VERSION ""

NS_ :

BS_:

BU_:
VAL_TABLE_ CurDivValid 1 "Valid" 0 "Invalid" ;
VAL_TABLE_ CurDivValid 1 "Description for the value '0x1'" 0 "Invalid" ;
VAL_TABLE_ Validity 1 "Valid" 0 "Invalid" ;
VAL_TABLE_ Model_Degree 2 "3rd-Degree Model" 1 "Linear model" 0 "Parabolic Model" ;
VAL_TABLE_ Quality 3 "High Quality" 2 "High Quality" 1 "Low Quality" 0 "Low Quality" ;
VAL_TABLE_ Lane_Type 6 "Invalid" 5 "Botts' dots" 4 "Double lane mark" 3 "Road edge" 2 "Undecided" 1 "Solid" 0 "Dashed" ;
VAL_TABLE_ Ref_Point_2_Validity 1 "Valid" 0 "Invalid" ;
VAL_TABLE_ Ref_Point_1_Validity 1 "Valid" 0 "Invalid" ;
VAL_TABLE_ View_Ragne_Availability 1 "Valid" 0 "Not Valid" ;
VAL_TABLE_ Model_Degree 2 "3rd-degree model" 1 "Linear model" 0 "Parabolic model" ;
VAL_TABLE_ Quality 3 "High quality" 2 "High quality" 1 "Low quality" 0 "Low quality" ;
VAL_TABLE_ Lane_Type 6 "invalid" 5 "Bott's Dots" 4 "Double Lane" 3 "Road Edge" 2 "undecided" 1 "Solid" 0 "Dashed" ;

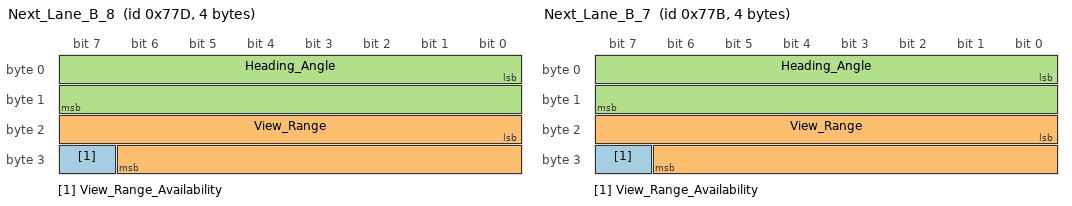
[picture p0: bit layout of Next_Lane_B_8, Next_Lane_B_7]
BO_ 1917 Next_Lane_B_8: 4 Vector__XXX
 SG_ View_Range_Availability : 31|1@1+ (1,0) [0|0] "" Vector__XXX
 SG_ View_Range : 16|15@1+ (0.00390625,0) [0|127.99609375] "meter" Vector__XXX
 SG_ Heading_Angle : 0|16@1+ (0.0009765625,-31.9990234375) [-0.357|0.357] "radians" Vector__XXX

BO_ 1915 Next_Lane_B_7: 4 Vector__XXX
 SG_ View_Range_Availability : 31|1@1+ (1,0) [0|0] "" Vector__XXX
 SG_ View_Range : 16|15@1+ (0.00390625,0) [0|127.99609375] "meter" Vector__XXX
 SG_ Heading_Angle : 0|16@1+ (0.0009765625,-31.9990234375) [-0.357|0.357] "radians" Vector__XXX

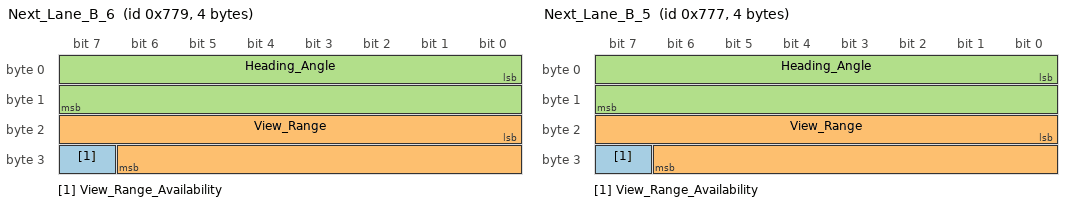
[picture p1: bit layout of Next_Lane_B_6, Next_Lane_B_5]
BO_ 1913 Next_Lane_B_6: 4 Vector__XXX
 SG_ View_Range_Availability : 31|1@1+ (1,0) [0|0] "" Vector__XXX
 SG_ View_Range : 16|15@1+ (0.00390625,0) [0|127.99609375] "meter" Vector__XXX
 SG_ Heading_Angle : 0|16@1+ (0.0009765625,-31.9990234375) [-0.357|0.357] "radians" Vector__XXX

BO_ 1911 Next_Lane_B_5: 4 Vector__XXX
 SG_ View_Range_Availability : 31|1@1+ (1,0) [0|0] "" Vector__XXX
 SG_ View_Range : 16|15@1+ (0.00390625,0) [0|127.99609375] "meter" Vector__XXX
 SG_ Heading_Angle : 0|16@1+ (0.0009765625,-31.9990234375) [-0.357|0.357] "radians" Vector__XXX

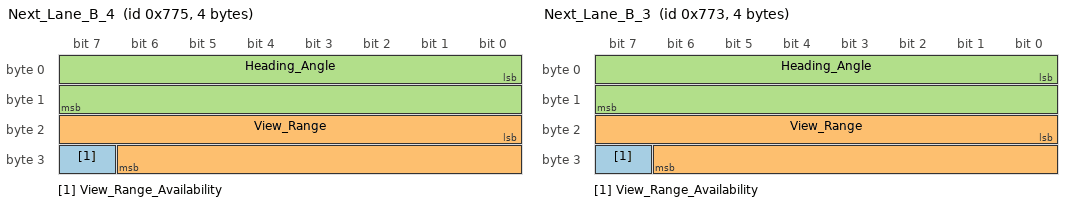
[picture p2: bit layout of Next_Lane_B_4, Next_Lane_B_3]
BO_ 1909 Next_Lane_B_4: 4 Vector__XXX
 SG_ View_Range_Availability : 31|1@1+ (1,0) [0|0] "" Vector__XXX
 SG_ View_Range : 16|15@1+ (0.00390625,0) [0|127.99609375] "meter" Vector__XXX
 SG_ Heading_Angle : 0|16@1+ (0.0009765625,-31.9990234375) [-0.357|0.357] "radians" Vector__XXX

BO_ 1907 Next_Lane_B_3: 4 Vector__XXX
 SG_ View_Range_Availability : 31|1@1+ (1,0) [0|0] "" Vector__XXX
 SG_ View_Range : 16|15@1+ (0.00390625,0) [0|127.99609375] "meter" Vector__XXX
 SG_ Heading_Angle : 0|16@1+ (0.0009765625,-31.9990234375) [-0.357|0.357] "radians" Vector__XXX

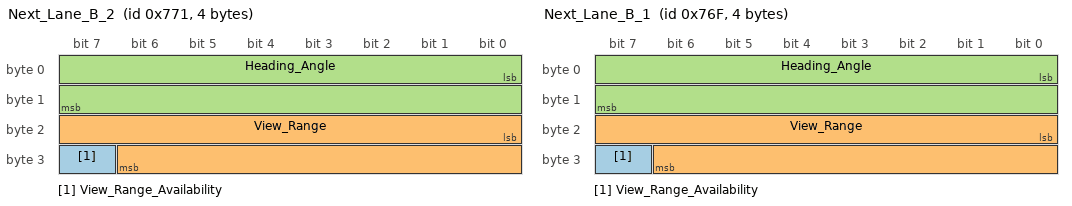
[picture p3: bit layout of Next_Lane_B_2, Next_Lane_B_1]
BO_ 1905 Next_Lane_B_2: 4 Vector__XXX
 SG_ View_Range_Availability : 31|1@1+ (1,0) [0|0] "" Vector__XXX
 SG_ View_Range : 16|15@1+ (0.00390625,0) [0|127.99609375] "meter" Vector__XXX
 SG_ Heading_Angle : 0|16@1+ (0.0009765625,-31.9990234375) [-0.357|0.357] "radians" Vector__XXX

BO_ 1903 Next_Lane_B_1: 4 Vector__XXX
 SG_ View_Range_Availability : 31|1@1+ (1,0) [0|0] "" Vector__XXX
 SG_ View_Range : 16|15@1+ (0.00390625,0) [0|127.99609375] "meter" Vector__XXX
 SG_ Heading_Angle : 0|16@1+ (0.0009765625,-31.9990234375) [-0.357|0.357] "radians" Vector__XXX

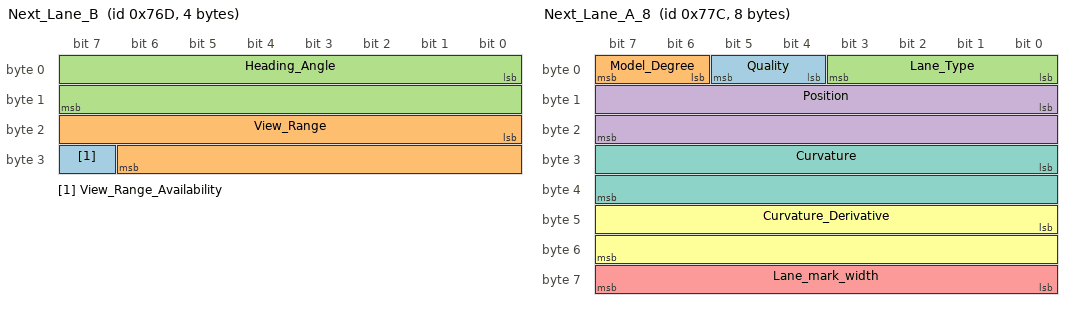
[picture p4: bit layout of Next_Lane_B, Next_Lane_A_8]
BO_ 1901 Next_Lane_B: 4 Vector__XXX
 SG_ View_Range_Availability : 31|1@1+ (1,0) [0|0] "" Vector__XXX
 SG_ View_Range : 16|15@1+ (0.00390625,0) [0|127.99609375] "meter" Vector__XXX
 SG_ Heading_Angle : 0|16@1+ (0.0009765625,-31.9990234375) [-0.357|0.357] "radians" Vector__XXX

BO_ 1916 Next_Lane_A_8: 8 Vector__XXX
 SG_ Quality : 4|2@1+ (1,0) [0|0] "" Vector__XXX
 SG_ Model_Degree : 6|2@1+ (1,0) [0|0] "" Vector__XXX
 SG_ Lane_Type : 0|4@1+ (1,0) [0|0] "" Vector__XXX
 SG_ Position : 8|16@1- (0.00390625,0) [-128|127] "meter" Vector__XXX
 SG_ Lane_mark_width : 56|8@1+ (0.01,0) [0|2.5] "meter" Vector__XXX
 SG_ Curvature_Derivative : 40|16@1+ (3.7252902985E-009,-0.00012206658721) [-0.00012|0.00012] "1/meter^2" Vector__XXX
 SG_ Curvature : 24|16@1+ (9.765625E-007,-0.031999023438) [-0.02|0.02] "1/meter" Vector__XXX

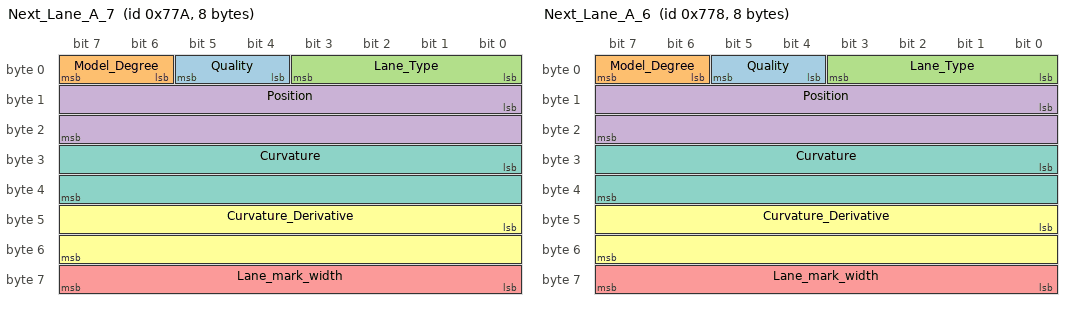
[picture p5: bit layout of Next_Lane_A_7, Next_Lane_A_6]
BO_ 1914 Next_Lane_A_7: 8 Vector__XXX
 SG_ Quality : 4|2@1+ (1,0) [0|0] "" Vector__XXX
 SG_ Model_Degree : 6|2@1+ (1,0) [0|0] "" Vector__XXX
 SG_ Lane_Type : 0|4@1+ (1,0) [0|0] "" Vector__XXX
 SG_ Position : 8|16@1- (0.00390625,0) [-128|127] "meter" Vector__XXX
 SG_ Lane_mark_width : 56|8@1+ (0.01,0) [0|2.5] "meter" Vector__XXX
 SG_ Curvature_Derivative : 40|16@1+ (3.7252902985E-009,-0.00012206658721) [-0.00012|0.00012] "1/meter^2" Vector__XXX
 SG_ Curvature : 24|16@1+ (9.765625E-007,-0.031999023438) [-0.02|0.02] "1/meter" Vector__XXX

BO_ 1912 Next_Lane_A_6: 8 Vector__XXX
 SG_ Quality : 4|2@1+ (1,0) [0|0] "" Vector__XXX
 SG_ Model_Degree : 6|2@1+ (1,0) [0|0] "" Vector__XXX
 SG_ Lane_Type : 0|4@1+ (1,0) [0|0] "" Vector__XXX
 SG_ Position : 8|16@1- (0.00390625,0) [-128|127] "meter" Vector__XXX
 SG_ Lane_mark_width : 56|8@1+ (0.01,0) [0|2.5] "meter" Vector__XXX
 SG_ Curvature_Derivative : 40|16@1+ (3.7252902985E-009,-0.00012206658721) [-0.00012|0.00012] "1/meter^2" Vector__XXX
 SG_ Curvature : 24|16@1+ (9.765625E-007,-0.031999023438) [-0.02|0.02] "1/meter" Vector__XXX

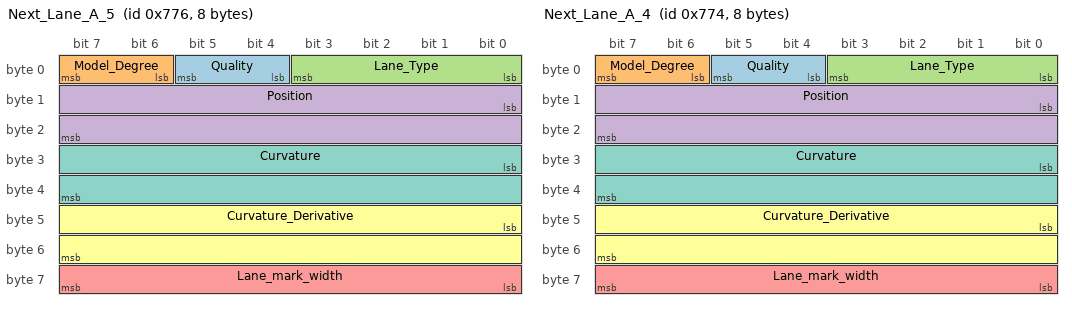
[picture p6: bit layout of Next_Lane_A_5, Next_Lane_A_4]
BO_ 1910 Next_Lane_A_5: 8 Vector__XXX
 SG_ Quality : 4|2@1+ (1,0) [0|0] "" Vector__XXX
 SG_ Model_Degree : 6|2@1+ (1,0) [0|0] "" Vector__XXX
 SG_ Lane_Type : 0|4@1+ (1,0) [0|0] "" Vector__XXX
 SG_ Position : 8|16@1- (0.00390625,0) [-128|127] "meter" Vector__XXX
 SG_ Lane_mark_width : 56|8@1+ (0.01,0) [0|2.5] "meter" Vector__XXX
 SG_ Curvature_Derivative : 40|16@1+ (3.7252902985E-009,-0.00012206658721) [-0.00012|0.00012] "1/meter^2" Vector__XXX
 SG_ Curvature : 24|16@1+ (9.765625E-007,-0.031999023438) [-0.02|0.02] "1/meter" Vector__XXX

BO_ 1908 Next_Lane_A_4: 8 Vector__XXX
 SG_ Quality : 4|2@1+ (1,0) [0|0] "" Vector__XXX
 SG_ Model_Degree : 6|2@1+ (1,0) [0|0] "" Vector__XXX
 SG_ Lane_Type : 0|4@1+ (1,0) [0|0] "" Vector__XXX
 SG_ Position : 8|16@1- (0.00390625,0) [-128|127] "meter" Vector__XXX
 SG_ Lane_mark_width : 56|8@1+ (0.01,0) [0|2.5] "meter" Vector__XXX
 SG_ Curvature_Derivative : 40|16@1+ (3.7252902985E-009,-0.00012206658721) [-0.00012|0.00012] "1/meter^2" Vector__XXX
 SG_ Curvature : 24|16@1+ (9.765625E-007,-0.031999023438) [-0.02|0.02] "1/meter" Vector__XXX

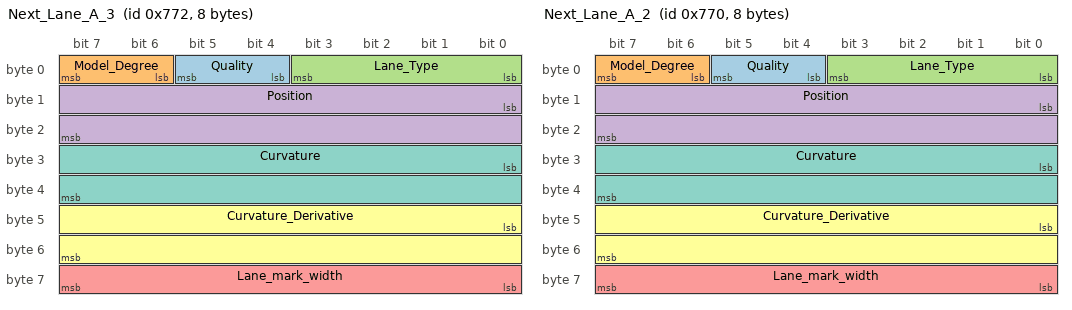
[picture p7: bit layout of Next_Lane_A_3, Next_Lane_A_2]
BO_ 1906 Next_Lane_A_3: 8 Vector__XXX
 SG_ Quality : 4|2@1+ (1,0) [0|0] "" Vector__XXX
 SG_ Model_Degree : 6|2@1+ (1,0) [0|0] "" Vector__XXX
 SG_ Lane_Type : 0|4@1+ (1,0) [0|0] "" Vector__XXX
 SG_ Position : 8|16@1- (0.00390625,0) [-128|127] "meter" Vector__XXX
 SG_ Lane_mark_width : 56|8@1+ (0.01,0) [0|2.5] "meter" Vector__XXX
 SG_ Curvature_Derivative : 40|16@1+ (3.7252902985E-009,-0.00012206658721) [-0.00012|0.00012] "1/meter^2" Vector__XXX
 SG_ Curvature : 24|16@1+ (9.765625E-007,-0.031999023438) [-0.02|0.02] "1/meter" Vector__XXX

BO_ 1904 Next_Lane_A_2: 8 Vector__XXX
 SG_ Quality : 4|2@1+ (1,0) [0|0] "" Vector__XXX
 SG_ Model_Degree : 6|2@1+ (1,0) [0|0] "" Vector__XXX
 SG_ Lane_Type : 0|4@1+ (1,0) [0|0] "" Vector__XXX
 SG_ Position : 8|16@1- (0.00390625,0) [-128|127] "meter" Vector__XXX
 SG_ Lane_mark_width : 56|8@1+ (0.01,0) [0|2.5] "meter" Vector__XXX
 SG_ Curvature_Derivative : 40|16@1+ (3.7252902985E-009,-0.00012206658721) [-0.00012|0.00012] "1/meter^2" Vector__XXX
 SG_ Curvature : 24|16@1+ (9.765625E-007,-0.031999023438) [-0.02|0.02] "1/meter" Vector__XXX

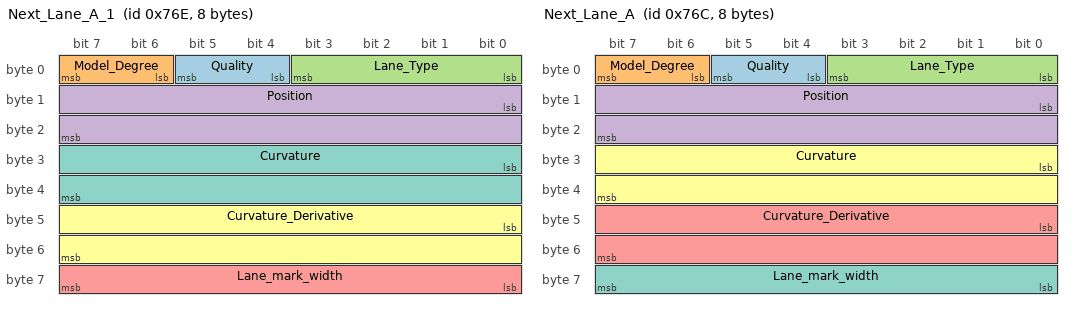
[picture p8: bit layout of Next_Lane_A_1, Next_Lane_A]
BO_ 1902 Next_Lane_A_1: 8 Vector__XXX
 SG_ Quality : 4|2@1+ (1,0) [0|0] "" Vector__XXX
 SG_ Model_Degree : 6|2@1+ (1,0) [0|0] "" Vector__XXX
 SG_ Lane_Type : 0|4@1+ (1,0) [0|0] "" Vector__XXX
 SG_ Position : 8|16@1- (0.00390625,0) [-128|127] "meter" Vector__XXX
 SG_ Lane_mark_width : 56|8@1+ (0.01,0) [0|2.5] "meter" Vector__XXX
 SG_ Curvature_Derivative : 40|16@1+ (3.7252902985E-009,-0.00012206658721) [-0.00012|0.00012] "1/meter^2" Vector__XXX
 SG_ Curvature : 24|16@1+ (9.765625E-007,-0.031999023438) [-0.02|0.02] "1/meter" Vector__XXX

BO_ 1900 Next_Lane_A: 8 Vector__XXX
 SG_ Quality : 4|2@1+ (1,0) [0|0] "" Vector__XXX
 SG_ Model_Degree : 6|2@1+ (1,0) [0|0] "" Vector__XXX
 SG_ Lane_Type : 0|4@1+ (1,0) [0|0] "" Vector__XXX
 SG_ Position : 8|16@1- (0.00390625,0) [-128|127] "meter" Vector__XXX
 SG_ Curvature_Derivative : 40|16@1+ (3.7252902985E-009,-0.00012206658721) [-0.00012|0.00012] "1/meter^2" Vector__XXX
 SG_ Curvature : 24|16@1+ (9.765625E-007,-0.031999023438) [-0.02|0.02] "1/meter" Vector__XXX
 SG_ Lane_mark_width : 56|8@1+ (0.01,0) [0|2.5] "meter" Vector__XXX

BO_ 1899 Num_Of_Next_Lane_Marks_Reported: 1 Vector__XXX
 SG_ Num_Of_Next_Lane_Mark_Reported : 7|8@0+ (1,0) [0|0] "Number of next lane markers" Vector__XXX

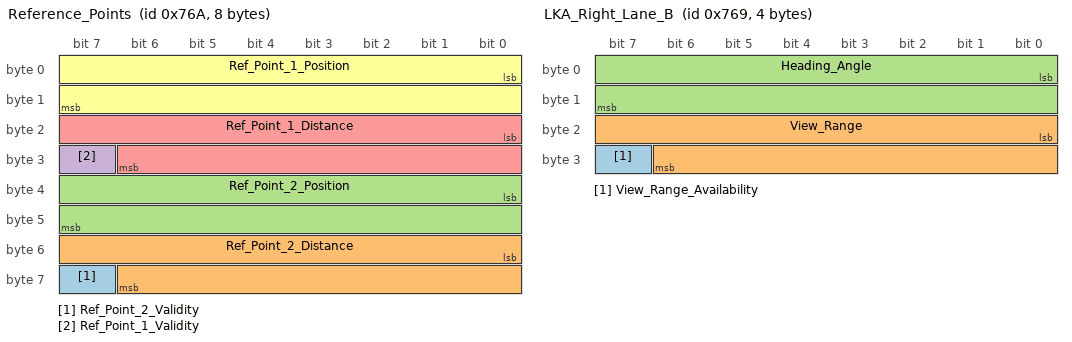
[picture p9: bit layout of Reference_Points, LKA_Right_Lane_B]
BO_ 1898 Reference_Points: 8 Vector__XXX
 SG_ Ref_Point_2_Validity : 63|1@0+ (1,0) [0|0] "" Vector__XXX
 SG_ Ref_Point_2_Distance : 48|15@1+ (0.00390625,0) [0|127.99609375] "meters" Vector__XXX
 SG_ Ref_Point_2_Position : 32|16@1+ (0.00390625,-127.99609375) [-127.99609375|128] "meters" Vector__XXX
 SG_ Ref_Point_1_Validity : 31|1@0+ (1,0) [0|0] "" Vector__XXX
 SG_ Ref_Point_1_Distance : 16|15@1+ (0.00390625,0) [0|127.99609375] "meters" Vector__XXX
 SG_ Ref_Point_1_Position : 0|16@1+ (0.00390625,-127.99609375) [-127.99609375|128] "meters" Vector__XXX

BO_ 1897 LKA_Right_Lane_B: 4 Vector__XXX
 SG_ View_Range_Availability : 31|1@1+ (1,0) [0|0] "" Vector__XXX
 SG_ View_Range : 16|15@1+ (0.00390625,0) [0|127.99609375] "meter" Vector__XXX
 SG_ Heading_Angle : 0|16@1+ (0.0009765625,-31.9990234375) [-0.357|0.357] "radians" Vector__XXX

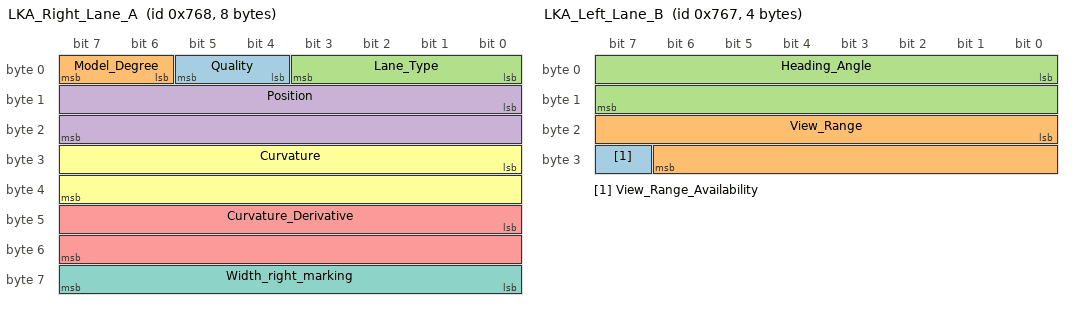
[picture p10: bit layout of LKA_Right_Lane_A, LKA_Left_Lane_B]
BO_ 1896 LKA_Right_Lane_A: 8 Vector__XXX
 SG_ Quality : 4|2@1+ (1,0) [0|0] "" Vector__XXX
 SG_ Model_Degree : 6|2@1+ (1,0) [0|0] "" Vector__XXX
 SG_ Lane_Type : 0|4@1+ (1,0) [0|0] "" Vector__XXX
 SG_ Position : 8|16@1- (0.00390625,0) [-128|127] "meter" Vector__XXX
 SG_ Curvature_Derivative : 40|16@1+ (3.7252902985E-009,-0.00012206658721) [-0.00012|0.00012] "1/meter^2" Vector__XXX
 SG_ Curvature : 24|16@1+ (9.765625E-007,-0.031999023438) [-0.02|0.02] "1/meter" Vector__XXX
 SG_ Width_right_marking : 56|8@1+ (0.01,0) [0|2.55] "m" Vector__XXX

BO_ 1895 LKA_Left_Lane_B: 4 Vector__XXX
 SG_ View_Range_Availability : 31|1@1+ (1,0) [0|0] "" Vector__XXX
 SG_ View_Range : 16|15@1+ (0.00390625,0) [0|127.99609375] "meter" Vector__XXX
 SG_ Heading_Angle : 0|16@1+ (0.0009765625,-31.9990234375) [-0.357|0.357] "radians" Vector__XXX

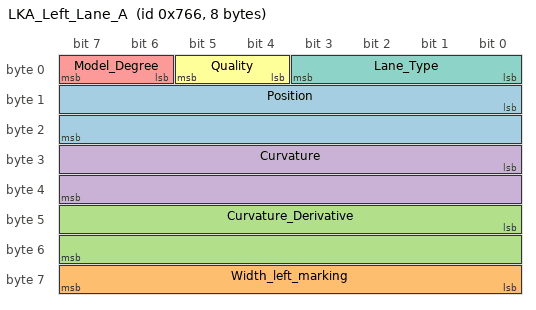
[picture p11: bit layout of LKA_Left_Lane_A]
BO_ 1894 LKA_Left_Lane_A: 8 Vector__XXX
 SG_ Position : 8|16@1- (0.00390625,0) [-128|127] "meter" Vector__XXX
 SG_ Width_left_marking : 56|8@1+ (0.01,0) [0|2.5] "m" Vector__XXX
 SG_ Curvature_Derivative : 40|16@1+ (3.7252902985E-009,-0.00012206658721) [-0.00012|0.00012] "1/meter^2" Vector__XXX
 SG_ Curvature : 24|16@1+ (9.765625E-007,-0.031999023438) [-0.02|0.02] "1/meter" Vector__XXX
 SG_ Model_Degree : 6|2@1+ (1,0) [0|0] "" Vector__XXX
 SG_ Quality : 4|2@1+ (1,0) [0|0] "" Vector__XXX
 SG_ Lane_Type : 0|4@1+ (1,0) [0|0] "" Vector__XXX

BA_DEF_  "BusType" STRING ;
BA_DEF_DEF_  "BusType" "CAN";
VAL_ 1917 View_Range_Availability 1 "Valid" 0 "Not Valid" ;
VAL_ 1915 View_Range_Availability 1 "Valid" 0 "Not Valid" ;
VAL_ 1913 View_Range_Availability 1 "Valid" 0 "Not Valid" ;
VAL_ 1911 View_Range_Availability 1 "Valid" 0 "Not Valid" ;
VAL_ 1909 View_Range_Availability 1 "Valid" 0 "Not Valid" ;
VAL_ 1907 View_Range_Availability 1 "Valid" 0 "Not Valid" ;
VAL_ 1905 View_Range_Availability 1 "Valid" 0 "Not Valid" ;
VAL_ 1903 View_Range_Availability 1 "Valid" 0 "Not Valid" ;
VAL_ 1901 View_Range_Availability 1 "Valid" 0 "Not Valid" ;
VAL_ 1916 Quality 3 "High quality" 2 "High quality" 1 "Low quality" 0 "Low quality" ;
VAL_ 1916 Model_Degree 2 "3rd-degree model" 1 "Linear model" 0 "Parabolic model" ;
VAL_ 1916 Lane_Type 6 "invalid" 5 "Bott's Dots" 4 "Double Lane" 3 "Road Edge" 2 "undecided" 1 "Solid" 0 "Dashed" ;
VAL_ 1914 Quality 3 "High quality" 2 "High quality" 1 "Low quality" 0 "Low quality" ;
VAL_ 1914 Model_Degree 2 "3rd-degree model" 1 "Linear model" 0 "Parabolic model" ;
VAL_ 1914 Lane_Type 6 "invalid" 5 "Bott's Dots" 4 "Double Lane" 3 "Road Edge" 2 "undecided" 1 "Solid" 0 "Dashed" ;
VAL_ 1912 Quality 3 "High quality" 2 "High quality" 1 "Low quality" 0 "Low quality" ;
VAL_ 1912 Model_Degree 2 "3rd-degree model" 1 "Linear model" 0 "Parabolic model" ;
VAL_ 1912 Lane_Type 6 "invalid" 5 "Bott's Dots" 4 "Double Lane" 3 "Road Edge" 2 "undecided" 1 "Solid" 0 "Dashed" ;
VAL_ 1910 Quality 3 "High quality" 2 "High quality" 1 "Low quality" 0 "Low quality" ;
VAL_ 1910 Model_Degree 2 "3rd-degree model" 1 "Linear model" 0 "Parabolic model" ;
VAL_ 1910 Lane_Type 6 "invalid" 5 "Bott's Dots" 4 "Double Lane" 3 "Road Edge" 2 "undecided" 1 "Solid" 0 "Dashed" ;
VAL_ 1908 Quality 3 "High quality" 2 "High quality" 1 "Low quality" 0 "Low quality" ;
VAL_ 1908 Model_Degree 2 "3rd-degree model" 1 "Linear model" 0 "Parabolic model" ;
VAL_ 1908 Lane_Type 6 "invalid" 5 "Bott's Dots" 4 "Double Lane" 3 "Road Edge" 2 "undecided" 1 "Solid" 0 "Dashed" ;
VAL_ 1906 Quality 3 "High quality" 2 "High quality" 1 "Low quality" 0 "Low quality" ;
VAL_ 1906 Model_Degree 2 "3rd-degree model" 1 "Linear model" 0 "Parabolic model" ;
VAL_ 1906 Lane_Type 6 "invalid" 5 "Bott's Dots" 4 "Double Lane" 3 "Road Edge" 2 "undecided" 1 "Solid" 0 "Dashed" ;
VAL_ 1904 Quality 3 "High quality" 2 "High quality" 1 "Low quality" 0 "Low quality" ;
VAL_ 1904 Model_Degree 2 "3rd-degree model" 1 "Linear model" 0 "Parabolic model" ;
VAL_ 1904 Lane_Type 6 "invalid" 5 "Bott's Dots" 4 "Double Lane" 3 "Road Edge" 2 "undecided" 1 "Solid" 0 "Dashed" ;
VAL_ 1902 Quality 3 "High quality" 2 "High quality" 1 "Low quality" 0 "Low quality" ;
VAL_ 1902 Model_Degree 2 "3rd-degree model" 1 "Linear model" 0 "Parabolic model" ;
VAL_ 1902 Lane_Type 6 "invalid" 5 "Bott's Dots" 4 "Double Lane" 3 "Road Edge" 2 "undecided" 1 "Solid" 0 "Dashed" ;
VAL_ 1900 Quality 3 "High quality" 2 "High quality" 1 "Low quality" 0 "Low quality" ;
VAL_ 1900 Model_Degree 2 "3rd-degree model" 1 "Linear model" 0 "Parabolic model" ;
VAL_ 1900 Lane_Type 6 "invalid" 5 "Bott's Dots" 4 "Double Lane" 3 "Road Edge" 2 "undecided" 1 "Solid" 0 "Dashed" ;
VAL_ 1897 View_Range_Availability 1 "Valid" 0 "Not Valid" ;
VAL_ 1896 Quality 3 "High quality" 2 "High quality" 1 "Low quality" 0 "Low quality" ;
VAL_ 1896 Model_Degree 2 "3rd-degree model" 1 "Linear model" 0 "Parabolic model" ;
VAL_ 1896 Lane_Type 6 "invalid" 5 "Bott's Dots" 4 "Double Lane" 3 "Road Edge" 2 "undecided" 1 "Solid" 0 "Dashed" ;
VAL_ 1895 View_Range_Availability 1 "Valid" 0 "Not Valid" ;
VAL_ 1894 Model_Degree 2 "3rd-degree model" 1 "Linear model" 0 "Parabolic model" ;
VAL_ 1894 Quality 3 "High quality" 2 "High quality" 1 "Low quality" 0 "Low quality" ;
VAL_ 1894 Lane_Type 6 "invalid" 5 "Bott's Dots" 4 "Double Lane" 3 "Road Edge" 2 "undecided" 1 "Solid" 0 "Dashed" ;
